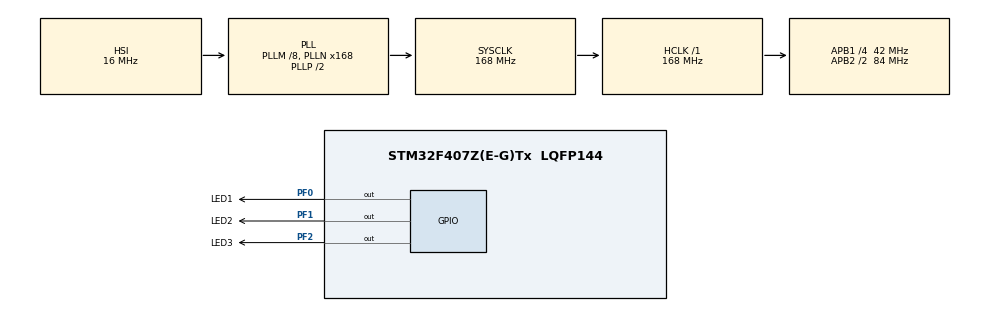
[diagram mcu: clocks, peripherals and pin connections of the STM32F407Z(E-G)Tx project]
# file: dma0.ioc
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Dma.MEMTOMEM.0.Direction=DMA_MEMORY_TO_MEMORY
Dma.MEMTOMEM.0.FIFOMode=DMA_FIFOMODE_ENABLE
Dma.MEMTOMEM.0.FIFOThreshold=DMA_FIFO_THRESHOLD_FULL
Dma.MEMTOMEM.0.Instance=DMA2_Stream0
Dma.MEMTOMEM.0.MemBurst=DMA_MBURST_SINGLE
Dma.MEMTOMEM.0.MemDataAlignment=DMA_MDATAALIGN_WORD
Dma.MEMTOMEM.0.MemInc=DMA_MINC_ENABLE
Dma.MEMTOMEM.0.Mode=DMA_NORMAL
Dma.MEMTOMEM.0.PeriphBurst=DMA_PBURST_SINGLE
Dma.MEMTOMEM.0.PeriphDataAlignment=DMA_PDATAALIGN_WORD
Dma.MEMTOMEM.0.PeriphInc=DMA_PINC_ENABLE
Dma.MEMTOMEM.0.Priority=DMA_PRIORITY_HIGH
Dma.Request0=MEMTOMEM
Mcu.Family=STM32F4
Mcu.Name=STM32F407Z(E-G)Tx
Mcu.Package=LQFP144
NVIC.PriorityGroup=NVIC_PRIORITYGROUP_4
PF0.GPIO_Label=LED1
PF0.PinState=GPIO_PIN_SET
PF0.Signal=GPIO_Output
PF1.GPIO_Label=LED2
PF1.PinState=GPIO_PIN_SET
PF1.Signal=GPIO_Output
PF2.GPIO_Label=LED3
PF2.PinState=GPIO_PIN_SET
PF2.Signal=GPIO_Output
PH0-OSC_IN.Mode=HSE-External-Oscillator
PH0-OSC_IN.Signal=RCC_OSC_IN
PH1-OSC_OUT.Mode=HSE-External-Oscillator
PH1-OSC_OUT.Signal=RCC_OSC_OUT
ProjectManager.HeapSize=0x200
ProjectManager.StackSize=0x400
ProjectManager.TargetToolchain=MDK-ARM V5
RCC.48MHZClocksFreq_Value=84000000
RCC.AHBFreq_Value=168000000
RCC.APB1CLKDivider=RCC_HCLK_DIV4
RCC.APB1Freq_Value=42000000
RCC.APB1TimFreq_Value=84000000
RCC.APB2CLKDivider=RCC_HCLK_DIV2
RCC.APB2Freq_Value=84000000
RCC.APB2TimFreq_Value=168000000
RCC.CortexFreq_Value=168000000
RCC.HCLKFreq_Value=168000000
RCC.HSE_VALUE=25000000
RCC.HSI_VALUE=16000000
RCC.LSE_VALUE=32768
RCC.PLLM=8
RCC.PLLN=168
RCC.SYSCLKFreq_VALUE=168000000
RCC.SYSCLKSource=RCC_SYSCLKSOURCE_PLLCLK
RCC.VCOOutputFreq_Value=336000000
board=custom

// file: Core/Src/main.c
/* USER CODE BEGIN Header */
/**
  ******************************************************************************
  * @file           : main.c
  * @brief          : Main program body
  ******************************************************************************
  * @attention
  *
  * Copyright (c) 2022 STMicroelectronics.
  * All rights reserved.
  *
  * This software is licensed under terms that can be found in the LICENSE file
  * in the root directory of this software component.
  * If no LICENSE file comes with this software, it is provided AS-IS.
  *
  ******************************************************************************
  */
/* USER CODE END Header */
#include "main.h"

/* USER CODE BEGIN PTD */
typedef enum
{
 FAILED = 0,
 PASSED = !FAILED
} TestStatus;
static const uint32_t SRC_Const_Buffer[32]= {
 0x01020304,0x05060708,0x090A0B0C,0x0D0E0F10,
 0x11121314,0x15161718,0x191A1B1C,0x1D1E1F20,
 0x21222324,0x25262728,0x292A2B2C,0x2D2E2F30,
 0x31323334,0x35363738,0x393A3B3C,0x3D3E3F40,
 0x41424344,0x45464748,0x494A4B4C,0x4D4E4F50,
 0x51525354,0x55565758,0x595A5B5C,0x5D5E5F60,
 0x61626364,0x65666768,0x696A6B6C,0x6D6E6F70,
 0x71727374,0x75767778,0x797A7B7C,0x7D7E7F80};
static uint32_t DST_Buffer[32]={0};;
/* USER CODE END PTD */

/* USER CODE BEGIN PD */
 #define OK_ON HAL_GPIO_WritePin(LED1_GPIO_Port,LED1_Pin,GPIO_PIN_RESET);HAL_GPIO_WritePin(LED2_GPIO_Port,LED2_Pin,GPIO_PIN_SET);HAL_GPIO_WritePin(LED3_GPIO_Port,LED3_Pin,GPIO_PIN_SET)
 #define ERR_ON HAL_GPIO_WritePin(LED1_GPIO_Port,LED1_Pin,GPIO_PIN_SET);HAL_GPIO_WritePin(LED2_GPIO_Port,LED2_Pin,GPIO_PIN_RESET);HAL_GPIO_WritePin(LED3_GPIO_Port,LED3_Pin,GPIO_PIN_SET)
 #define UNSENT_ON HAL_GPIO_WritePin(LED1_GPIO_Port,LED1_Pin,GPIO_PIN_SET);HAL_GPIO_WritePin(LED2_GPIO_Port,LED2_Pin,GPIO_PIN_SET);HAL_GPIO_WritePin(LED3_GPIO_Port,LED3_Pin,GPIO_PIN_RESET)
/* USER CODE END PD */

 DMA_HandleTypeDef hdma_memtomem_dma2_stream0;

void SystemClock_Config(void);
static void MX_GPIO_Init(void);
static void MX_DMA_Init(void);
/* USER CODE BEGIN PFP */
TestStatus Buffercmp(const uint32_t* pBuffer,uint32_t* pBuffer1,uint16_t BufferLength);
/* USER CODE END PFP */

int main(void)
{
  /* USER CODE BEGIN 1 */
	HAL_StatusTypeDef har_status;
	TestStatus dma_stauts;
  /* USER CODE END 1 */

  /* MCU Configuration--------------------------------------------------------*/

  /* Reset of all peripherals, Initializes the Flash interface and the Systick. */
  HAL_Init();

  /* Configure the system clock */
  SystemClock_Config();

  /* Initialize all configured peripherals */
  MX_GPIO_Init();
  MX_DMA_Init();
  /* USER CODE BEGIN 2 */
	har_status= HAL_DMA_Start(&hdma_memtomem_dma2_stream0,(uint32_t)&SRC_Const_Buffer,(uint32_t)&DST_Buffer,32);
	if(har_status==HAL_OK){
		dma_stauts=Buffercmp(SRC_Const_Buffer,DST_Buffer,32);
		if(dma_stauts==PASSED){
			OK_ON;
		}
		else{
			ERR_ON;
		}
	}
	else{
		UNSENT_ON;
	}
  /* USER CODE END 2 */

  /* Infinite loop */
  while (1)
  {

  }
}

void SystemClock_Config(void)
{
  RCC_OscInitTypeDef RCC_OscInitStruct = {0};
  RCC_ClkInitTypeDef RCC_ClkInitStruct = {0};

  /** Configure the main internal regulator output voltage
  */
  __HAL_RCC_PWR_CLK_ENABLE();
  __HAL_PWR_VOLTAGESCALING_CONFIG(PWR_REGULATOR_VOLTAGE_SCALE1);

  /** Initializes the RCC Oscillators according to the specified parameters
  * in the RCC_OscInitTypeDef structure.
  */
  RCC_OscInitStruct.OscillatorType = RCC_OSCILLATORTYPE_HSI;
  RCC_OscInitStruct.HSIState = RCC_HSI_ON;
  RCC_OscInitStruct.HSICalibrationValue = RCC_HSICALIBRATION_DEFAULT;
  RCC_OscInitStruct.PLL.PLLState = RCC_PLL_ON;
  RCC_OscInitStruct.PLL.PLLSource = RCC_PLLSOURCE_HSI;
  RCC_OscInitStruct.PLL.PLLM = 8;
  RCC_OscInitStruct.PLL.PLLN = 168;
  RCC_OscInitStruct.PLL.PLLP = RCC_PLLP_DIV2;
  RCC_OscInitStruct.PLL.PLLQ = 4;
  if (HAL_RCC_OscConfig(&RCC_OscInitStruct) != HAL_OK)
  {
    Error_Handler();
  }

  /** Initializes the CPU, AHB and APB buses clocks
  */
  RCC_ClkInitStruct.ClockType = RCC_CLOCKTYPE_HCLK|RCC_CLOCKTYPE_SYSCLK
                              |RCC_CLOCKTYPE_PCLK1|RCC_CLOCKTYPE_PCLK2;
  RCC_ClkInitStruct.SYSCLKSource = RCC_SYSCLKSOURCE_PLLCLK;
  RCC_ClkInitStruct.AHBCLKDivider = RCC_SYSCLK_DIV1;
  RCC_ClkInitStruct.APB1CLKDivider = RCC_HCLK_DIV4;
  RCC_ClkInitStruct.APB2CLKDivider = RCC_HCLK_DIV2;

  if (HAL_RCC_ClockConfig(&RCC_ClkInitStruct, FLASH_LATENCY_5) != HAL_OK)
  {
    Error_Handler();
  }
}

static void MX_DMA_Init(void)
{

  /* DMA controller clock enable */
  __HAL_RCC_DMA2_CLK_ENABLE();

  /* Configure DMA request hdma_memtomem_dma2_stream0 on DMA2_Stream0 */
  hdma_memtomem_dma2_stream0.Instance = DMA2_Stream0;
  hdma_memtomem_dma2_stream0.Init.Channel = DMA_CHANNEL_0;
  hdma_memtomem_dma2_stream0.Init.Direction = DMA_MEMORY_TO_MEMORY;
  hdma_memtomem_dma2_stream0.Init.PeriphInc = DMA_PINC_ENABLE;
  hdma_memtomem_dma2_stream0.Init.MemInc = DMA_MINC_ENABLE;
  hdma_memtomem_dma2_stream0.Init.PeriphDataAlignment = DMA_PDATAALIGN_WORD;
  hdma_memtomem_dma2_stream0.Init.MemDataAlignment = DMA_MDATAALIGN_WORD;
  hdma_memtomem_dma2_stream0.Init.Mode = DMA_NORMAL;
  hdma_memtomem_dma2_stream0.Init.Priority = DMA_PRIORITY_HIGH;
  hdma_memtomem_dma2_stream0.Init.FIFOMode = DMA_FIFOMODE_ENABLE;
  hdma_memtomem_dma2_stream0.Init.FIFOThreshold = DMA_FIFO_THRESHOLD_FULL;
  hdma_memtomem_dma2_stream0.Init.MemBurst = DMA_MBURST_SINGLE;
  hdma_memtomem_dma2_stream0.Init.PeriphBurst = DMA_PBURST_SINGLE;
  if (HAL_DMA_Init(&hdma_memtomem_dma2_stream0) != HAL_OK)
  {
    Error_Handler( );
  }

}

static void MX_GPIO_Init(void)
{
  GPIO_InitTypeDef GPIO_InitStruct = {0};

  /* GPIO Ports Clock Enable */
  __HAL_RCC_GPIOF_CLK_ENABLE();
  __HAL_RCC_GPIOH_CLK_ENABLE();

  /*Configure GPIO pin Output Level */
  HAL_GPIO_WritePin(GPIOF, GPIO_PIN_0|GPIO_PIN_1|GPIO_PIN_2, GPIO_PIN_SET);

  /*Configure GPIO pins : PF0 PF1 PF2 */
  GPIO_InitStruct.Pin = GPIO_PIN_0|GPIO_PIN_1|GPIO_PIN_2;
  GPIO_InitStruct.Mode = GPIO_MODE_OUTPUT_PP;
  GPIO_InitStruct.Pull = GPIO_NOPULL;
  GPIO_InitStruct.Speed = GPIO_SPEED_FREQ_LOW;
  HAL_GPIO_Init(GPIOF, &GPIO_InitStruct);

}

/* USER CODE BEGIN 4 */
TestStatus Buffercmp(const uint32_t* pBuffer,uint32_t* pBuffer1,uint16_t BufferLength){
	while(BufferLength--){
		if(*pBuffer!=*pBuffer1){
			return FAILED;
		}
		pBuffer++;
		pBuffer1++;

	}
	return PASSED;
}
/* USER CODE END 4 */

void Error_Handler(void)
{
  __disable_irq();
  while (1)
  {
  }
}
